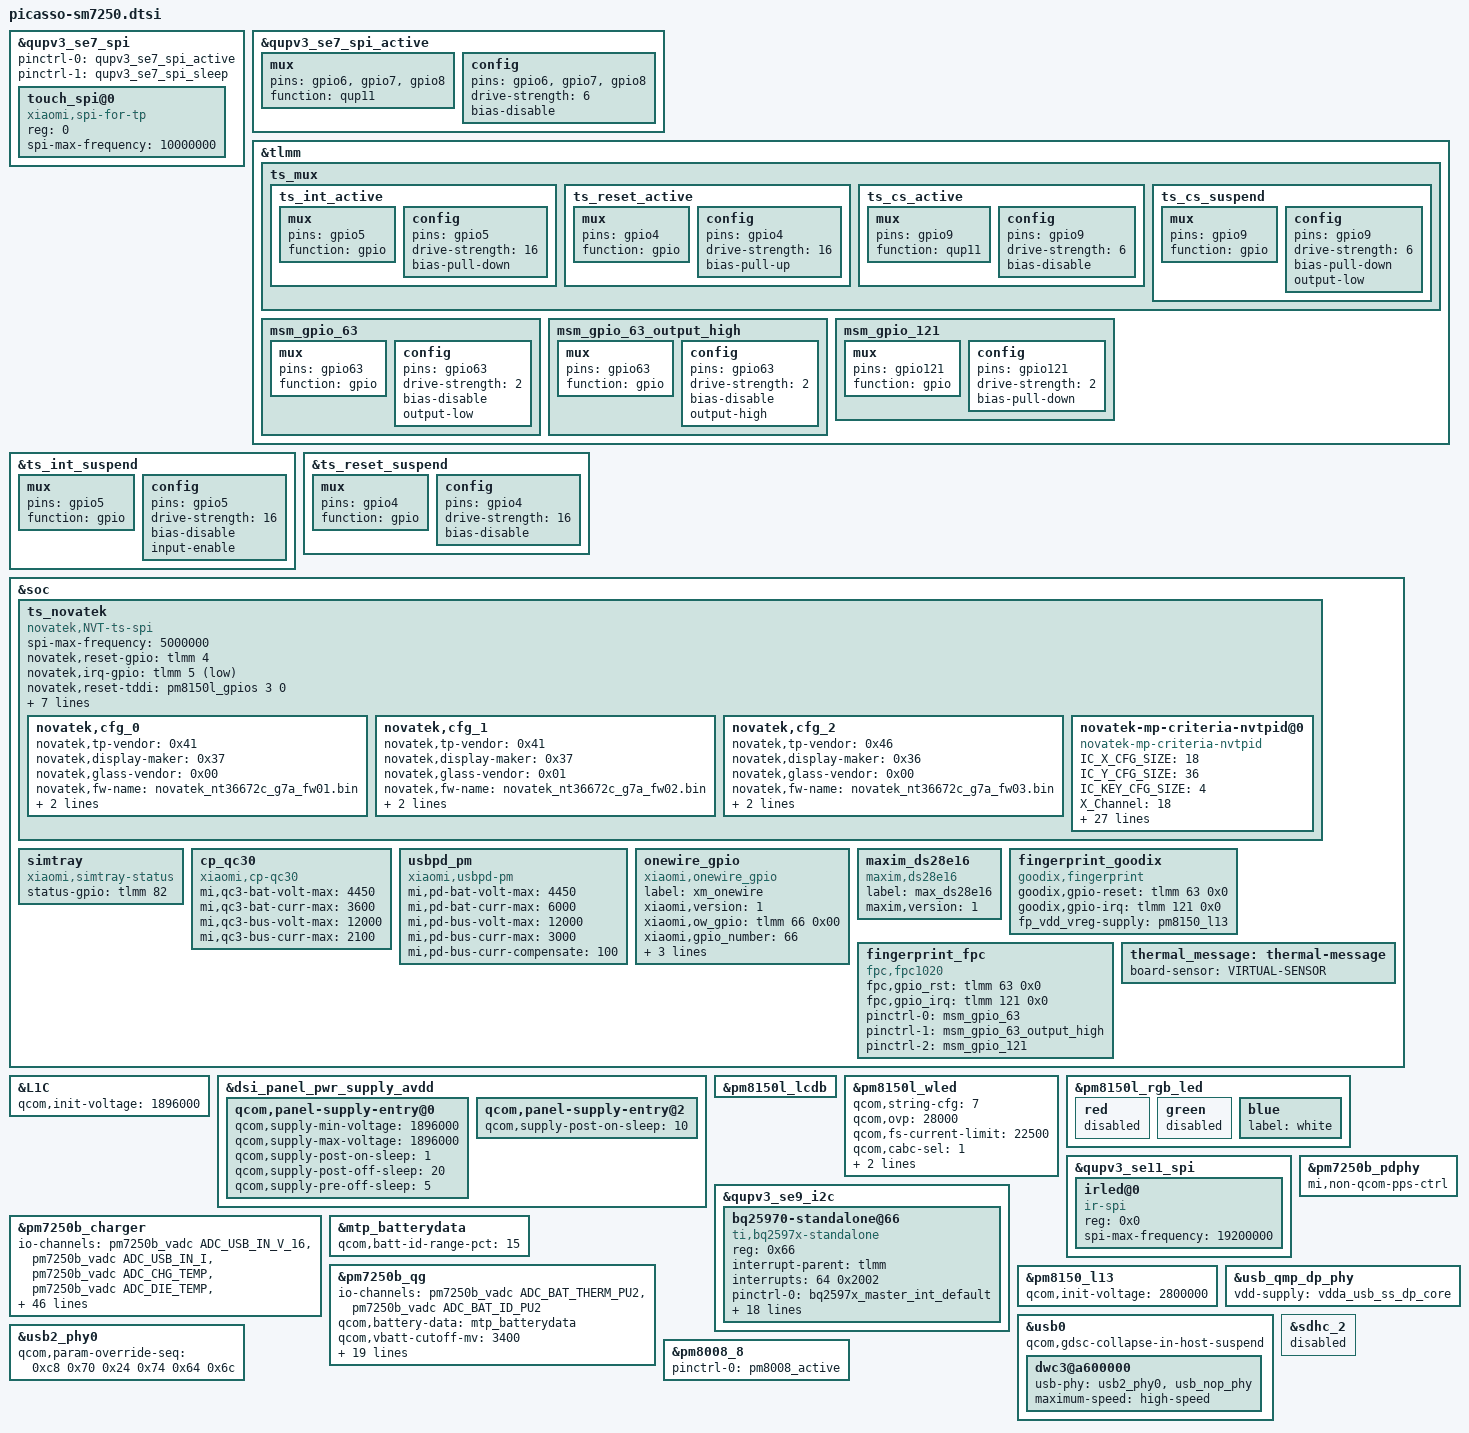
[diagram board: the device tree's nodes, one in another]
/* Copyright (c) 2018, The Linux Foundation. All rights reserved.
 * Copyright (C) 2021 XiaoMi, Inc.
 * Copyright (C) 2021 XiaoMi, Inc.
 *
 * This program is free software; you can redistribute it and/or modify
 * it under the terms of the GNU General Public License version 2 and
 * only version 2 as published by the Free Software Foundation.
 *
 * This program is distributed in the hope that it will be useful,
 * but WITHOUT ANY WARRANTY; without even the implied warranty of
 * MERCHANTABILITY or FITNESS FOR A PARTICULAR PURPOSE.  See the
 * GNU General Public License for more details.
 */

#include "xiaomi-sm7250-common.dtsi"
#include "picasso-sm7250-pinctrl.dtsi"

&qupv3_se7_spi {
	status = "ok";
	touch_spi@0 {
		compatible = "xiaomi,spi-for-tp";
		reg = <0>;
		status = "ok";
		spi-max-frequency = <10000000>;  //10M
	};
};

/*Touch SPI state init*/
&qupv3_se7_spi_active {
	mux {
		pins = "gpio6", "gpio7", "gpio8";
		function = "qup11";
	};

	config {
		pins = "gpio6", "gpio7", "gpio8";
		drive-strength = <6>;
		bias-disable;
	};
};

&qupv3_se7_spi {
	pinctrl-0 = <&qupv3_se7_spi_active>;
	pinctrl-1 = <&qupv3_se7_spi_sleep>;
};

/*IC int pin, rst pin init*/
&tlmm {
	ts_mux {
		ts_int_active: ts_int_active {
			mux {
				pins = "gpio5";
				function = "gpio";
			};

			config {
				pins = "gpio5";
				drive-strength = <16>;
				bias-pull-down;
			};
		};

		ts_reset_active: ts_reset_active {
			mux {
				pins = "gpio4";
				function = "gpio";
			};

			config {
				pins = "gpio4";
				drive-strength = <16>;
				bias-pull-up;
			};
		};
		ts_cs_active: ts_cs_active {
			mux {
				pins = "gpio9";
				function = "qup11";
			};

			config {
				pins = "gpio9";
				drive-strength = <6>;
				bias-disable;
			};
		};

		ts_cs_suspend: ts_cs_suspend {
			mux {
				pins = "gpio9";
				function = "gpio";
			};

			config {
				pins = "gpio9";
				drive-strength = <6>;
				bias-pull-down;
				output-low;
			};
		};
	};
};

&ts_int_suspend {
	mux {
		pins = "gpio5";
		function = "gpio";
	};

	config {
		pins = "gpio5";
		drive-strength = <16>;
		bias-disable;
		input-enable;
	};
};

&ts_reset_suspend {
	mux {
		pins = "gpio4";
		function = "gpio";
	};

	config {
		pins = "gpio4";
		drive-strength = <16>;
		bias-disable;
	};
};


/* Novatek device tree node */
&soc {
	ts_novatek {
			compatible = "novatek,NVT-ts-spi";
			status = "ok";

			spi-max-frequency = <5000000>;	//4800000,9600000,15000000,19200000 5M
			novatek,reset-gpio = <&tlmm 4 0x00>;
			novatek,irq-gpio = <&tlmm 5 0x2001>;
			novatek,reset-tddi = <&pm8150l_gpios 3 0>;
			pinctrl-names = "pmx_ts_active", "pmx_ts_suspend";
			pinctrl-0 = <&ts_int_active &ts_reset_active &ts_cs_active>;
			pinctrl-1 = <&ts_int_suspend &ts_reset_suspend &ts_cs_suspend>;
			/* 672 */
			//novatek,swrst-n8-addr = <0x01F01A>;

			/* 672A */
			novatek,swrst-n8-addr = <0x03F0FE>;
			novatek,spi-rd-fast-addr = <0x03F310>;

			novatek,config-array-size = <3>;
			novatek,cfg_0 {
				novatek,tp-vendor = <0x41>;
				novatek,display-maker = <0x37>;
				novatek,glass-vendor = <0x00>;
				novatek,fw-name = "novatek_nt36672c_g7a_fw01.bin";
				novatek,mp-name = "novatek_nt36672c_g7a_mp01.bin";
				novatek,clicknum-file-name = "nvt+ebbg";
			};
			novatek,cfg_1 {
				novatek,tp-vendor = <0x41>;
				novatek,display-maker = <0x37>;
				novatek,glass-vendor = <0x01>;
				novatek,fw-name = "novatek_nt36672c_g7a_fw02.bin";
				novatek,mp-name = "novatek_nt36672c_g7a_mp02.bin";
				novatek,clicknum-file-name = "nvt+ebbg";
			};
			novatek,cfg_2 {
				novatek,tp-vendor = <0x46>;
				novatek,display-maker = <0x36>;
				novatek,glass-vendor = <0x00>;
				novatek,fw-name = "novatek_nt36672c_g7a_fw03.bin";
				novatek,mp-name = "novatek_nt36672c_g7a_mp03.bin";
				novatek,clicknum-file-name = "nvt+ebbg";
			};

			/* MP */
			//novatek,mp-support-dt;


			novatek-mp-criteria-nvtpid@0 {
				#address-cells = <1>;
				#size-cells = <0>;
				compatible = "novatek-mp-criteria-nvtpid";

				/* MP Config */
				IC_X_CFG_SIZE = <18>;
				IC_Y_CFG_SIZE = <36>;
				IC_KEY_CFG_SIZE = <4>;
				X_Channel = <18>;
				Y_Channel = <36>;
				AIN_X = <0 1 2 3 4 5 6 7 8 9 10 11 12 13 14 15 16 17>;
				AIN_Y = <0 1 2 3 4 5 6 7 8 9 10 11 12 13 14 15 16 17
							18 19 20 21 22 23 24 25 26 27 28 29 30 31 32 33 34 35>;
				AIN_KEY = <0 1 2 0xFF>;

				/* MP Criteria */
				PS_Config_Lmt_Short_Rawdata_P = <
					14008 14008 14008 14008 14008 14008 14008 14008 14008 14008 14008 14008 14008 14008 14008 14008 14008 14008
					14008 14008 14008 14008 14008 14008 14008 14008 14008 14008 14008 14008 14008 14008 14008 14008 14008 14008
					14008 14008 14008 14008 14008 14008 14008 14008 14008 14008 14008 14008 14008 14008 14008 14008 14008 14008
					14008 14008 14008 14008 14008 14008 14008 14008 14008 14008 14008 14008 14008 14008 14008 14008 14008 14008
					14008 14008 14008 14008 14008 14008 14008 14008 14008 14008 14008 14008 14008 14008 14008 14008 14008 14008
					14008 14008 14008 14008 14008 14008 14008 14008 14008 14008 14008 14008 14008 14008 14008 14008 14008 14008
					14008 14008 14008 14008 14008 14008 14008 14008 14008 14008 14008 14008 14008 14008 14008 14008 14008 14008
					14008 14008 14008 14008 14008 14008 14008 14008 14008 14008 14008 14008 14008 14008 14008 14008 14008 14008
					14008 14008 14008 14008 14008 14008 14008 14008 14008 14008 14008 14008 14008 14008 14008 14008 14008 14008
					14008 14008 14008 14008 14008 14008 14008 14008 14008 14008 14008 14008 14008 14008 14008 14008 14008 14008
					14008 14008 14008 14008 14008 14008 14008 14008 14008 14008 14008 14008 14008 14008 14008 14008 14008 14008
					14008 14008 14008 14008 14008 14008 14008 14008 14008 14008 14008 14008 14008 14008 14008 14008 14008 14008
					14008 14008 14008 14008 14008 14008 14008 14008 14008 14008 14008 14008 14008 14008 14008 14008 14008 14008
					14008 14008 14008 14008 14008 14008 14008 14008 14008 14008 14008 14008 14008 14008 14008 14008 14008 14008
					14008 14008 14008 14008 14008 14008 14008 14008 14008 14008 14008 14008 14008 14008 14008 14008 14008 14008
					14008 14008 14008 14008 14008 14008 14008 14008 14008 14008 14008 14008 14008 14008 14008 14008 14008 14008
					14008 14008 14008 14008 14008 14008 14008 14008 14008 14008 14008 14008 14008 14008 14008 14008 14008 14008
					14008 14008 14008 14008 14008 14008 14008 14008 14008 14008 14008 14008 14008 14008 14008 14008 14008 14008
					14008 14008 14008 14008 14008 14008 14008 14008 14008 14008 14008 14008 14008 14008 14008 14008 14008 14008
					14008 14008 14008 14008 14008 14008 14008 14008 14008 14008 14008 14008 14008 14008 14008 14008 14008 14008
					14008 14008 14008 14008 14008 14008 14008 14008 14008 14008 14008 14008 14008 14008 14008 14008 14008 14008
					14008 14008 14008 14008 14008 14008 14008 14008 14008 14008 14008 14008 14008 14008 14008 14008 14008 14008
					14008 14008 14008 14008 14008 14008 14008 14008 14008 14008 14008 14008 14008 14008 14008 14008 14008 14008
					14008 14008 14008 14008 14008 14008 14008 14008 14008 14008 14008 14008 14008 14008 14008 14008 14008 14008
					14008 14008 14008 14008 14008 14008 14008 14008 14008 14008 14008 14008 14008 14008 14008 14008 14008 14008
					14008 14008 14008 14008 14008 14008 14008 14008 14008 14008 14008 14008 14008 14008 14008 14008 14008 14008
					14008 14008 14008 14008 14008 14008 14008 14008 14008 14008 14008 14008 14008 14008 14008 14008 14008 14008
					14008 14008 14008 14008 14008 14008 14008 14008 14008 14008 14008 14008 14008 14008 14008 14008 14008 14008
					14008 14008 14008 14008 14008 14008 14008 14008 14008 14008 14008 14008 14008 14008 14008 14008 14008 14008
					14008 14008 14008 14008 14008 14008 14008 14008 14008 14008 14008 14008 14008 14008 14008 14008 14008 14008
					14008 14008 14008 14008 14008 14008 14008 14008 14008 14008 14008 14008 14008 14008 14008 14008 14008 14008
					14008 14008 14008 14008 14008 14008 14008 14008 14008 14008 14008 14008 14008 14008 14008 14008 14008 14008
					14008 14008 14008 14008 14008 14008 14008 14008 14008 14008 14008 14008 14008 14008 14008 14008 14008 14008
					14008 14008 14008 14008 14008 14008 14008 14008 14008 14008 14008 14008 14008 14008 14008 14008 14008 14008
					14008 14008 14008 14008 14008 14008 14008 14008 14008 14008 14008 14008 14008 14008 14008 14008 14008 14008
					14008 14008 14008 14008 14008 14008 14008 14008 14008 14008 14008 14008 14008 14008 14008 14008 14008 14008
					14008 14008 14008>;

				PS_Config_Lmt_Short_Rawdata_N = <
					10000 10000 10000 10000 10000 10000 10000 10000 10000 10000 10000 10000 10000 10000 10000 10000 10000 10000
					10000 10000 10000 10000 10000 10000 10000 10000 10000 10000 10000 10000 10000 10000 10000 10000 10000 10000
					10000 10000 10000 10000 10000 10000 10000 10000 10000 10000 10000 10000 10000 10000 10000 10000 10000 10000
					10000 10000 10000 10000 10000 10000 10000 10000 10000 10000 10000 10000 10000 10000 10000 10000 10000 10000
					10000 10000 10000 10000 10000 10000 10000 10000 10000 10000 10000 10000 10000 10000 10000 10000 10000 10000
					10000 10000 10000 10000 10000 10000 10000 10000 10000 10000 10000 10000 10000 10000 10000 10000 10000 10000
					10000 10000 10000 10000 10000 10000 10000 10000 10000 10000 10000 10000 10000 10000 10000 10000 10000 10000
					10000 10000 10000 10000 10000 10000 10000 10000 10000 10000 10000 10000 10000 10000 10000 10000 10000 10000
					10000 10000 10000 10000 10000 10000 10000 10000 10000 10000 10000 10000 10000 10000 10000 10000 10000 10000
					10000 10000 10000 10000 10000 10000 10000 10000 10000 10000 10000 10000 10000 10000 10000 10000 10000 10000
					10000 10000 10000 10000 10000 10000 10000 10000 10000 10000 10000 10000 10000 10000 10000 10000 10000 10000
					10000 10000 10000 10000 10000 10000 10000 10000 10000 10000 10000 10000 10000 10000 10000 10000 10000 10000
					10000 10000 10000 10000 10000 10000 10000 10000 10000 10000 10000 10000 10000 10000 10000 10000 10000 10000
					10000 10000 10000 10000 10000 10000 10000 10000 10000 10000 10000 10000 10000 10000 10000 10000 10000 10000
					10000 10000 10000 10000 10000 10000 10000 10000 10000 10000 10000 10000 10000 10000 10000 10000 10000 10000
					10000 10000 10000 10000 10000 10000 10000 10000 10000 10000 10000 10000 10000 10000 10000 10000 10000 10000
					10000 10000 10000 10000 10000 10000 10000 10000 10000 10000 10000 10000 10000 10000 10000 10000 10000 10000
					10000 10000 10000 10000 10000 10000 10000 10000 10000 10000 10000 10000 10000 10000 10000 10000 10000 10000
					10000 10000 10000 10000 10000 10000 10000 10000 10000 10000 10000 10000 10000 10000 10000 10000 10000 10000
					10000 10000 10000 10000 10000 10000 10000 10000 10000 10000 10000 10000 10000 10000 10000 10000 10000 10000
					10000 10000 10000 10000 10000 10000 10000 10000 10000 10000 10000 10000 10000 10000 10000 10000 10000 10000
					10000 10000 10000 10000 10000 10000 10000 10000 10000 10000 10000 10000 10000 10000 10000 10000 10000 10000
					10000 10000 10000 10000 10000 10000 10000 10000 10000 10000 10000 10000 10000 10000 10000 10000 10000 10000
					10000 10000 10000 10000 10000 10000 10000 10000 10000 10000 10000 10000 10000 10000 10000 10000 10000 10000
					10000 10000 10000 10000 10000 10000 10000 10000 10000 10000 10000 10000 10000 10000 10000 10000 10000 10000
					10000 10000 10000 10000 10000 10000 10000 10000 10000 10000 10000 10000 10000 10000 10000 10000 10000 10000
					10000 10000 10000 10000 10000 10000 10000 10000 10000 10000 10000 10000 10000 10000 10000 10000 10000 10000
					10000 10000 10000 10000 10000 10000 10000 10000 10000 10000 10000 10000 10000 10000 10000 10000 10000 10000
					10000 10000 10000 10000 10000 10000 10000 10000 10000 10000 10000 10000 10000 10000 10000 10000 10000 10000
					10000 10000 10000 10000 10000 10000 10000 10000 10000 10000 10000 10000 10000 10000 10000 10000 10000 10000
					10000 10000 10000 10000 10000 10000 10000 10000 10000 10000 10000 10000 10000 10000 10000 10000 10000 10000
					10000 10000 10000 10000 10000 10000 10000 10000 10000 10000 10000 10000 10000 10000 10000 10000 10000 10000
					10000 10000 10000 10000 10000 10000 10000 10000 10000 10000 10000 10000 10000 10000 10000 10000 10000 10000
					10000 10000 10000 10000 10000 10000 10000 10000 10000 10000 10000 10000 10000 10000 10000 10000 10000 10000
					10000 10000 10000 10000 10000 10000 10000 10000 10000 10000 10000 10000 10000 10000 10000 10000 10000 10000
					10000 10000 10000 10000 10000 10000 10000 10000 10000 10000 10000 10000 10000 10000 10000 10000 10000 10000
					10000 10000 10000>;

				PS_Config_Lmt_Open_Rawdata_P = <
					4096 4096 4096 4096 4096 4096 4096 4096 4096 4096 4096 4096 4096 4096 4096 4096 4096 4096
					4096 4096 4096 4096 4096 4096 4096 4096 4096 4096 4096 4096 4096 4096 4096 4096 4096 4096
					4096 4096 4096 4096 4096 4096 4096 4096 4096 4096 4096 4096 4096 4096 4096 4096 4096 4096
					4096 4096 4096 4096 4096 4096 4096 4096 4096 4096 4096 4096 4096 4096 4096 4096 4096 4096
					4096 4096 4096 4096 4096 4096 4096 4096 4096 4096 4096 4096 4096 4096 4096 4096 4096 4096
					4096 4096 4096 4096 4096 4096 4096 4096 4096 4096 4096 4096 4096 4096 4096 4096 4096 4096
					4096 4096 4096 4096 4096 4096 4096 4096 4096 4096 4096 4096 4096 4096 4096 4096 4096 4096
					4096 4096 4096 4096 4096 4096 4096 4096 4096 4096 4096 4096 4096 4096 4096 4096 4096 4096
					4096 4096 4096 4096 4096 4096 4096 4096 4096 4096 4096 4096 4096 4096 4096 4096 4096 4096
					4096 4096 4096 4096 4096 4096 4096 4096 4096 4096 4096 4096 4096 4096 4096 4096 4096 4096
					4096 4096 4096 4096 4096 4096 4096 4096 4096 4096 4096 4096 4096 4096 4096 4096 4096 4096
					4096 4096 4096 4096 4096 4096 4096 4096 4096 4096 4096 4096 4096 4096 4096 4096 4096 4096
					4096 4096 4096 4096 4096 4096 4096 4096 4096 4096 4096 4096 4096 4096 4096 4096 4096 4096
					4096 4096 4096 4096 4096 4096 4096 4096 4096 4096 4096 4096 4096 4096 4096 4096 4096 4096
					4096 4096 4096 4096 4096 4096 4096 4096 4096 4096 4096 4096 4096 4096 4096 4096 4096 4096
					4096 4096 4096 4096 4096 4096 4096 4096 4096 4096 4096 4096 4096 4096 4096 4096 4096 4096
					4096 4096 4096 4096 4096 4096 4096 4096 4096 4096 4096 4096 4096 4096 4096 4096 4096 4096
					4096 4096 4096 4096 4096 4096 4096 4096 4096 4096 4096 4096 4096 4096 4096 4096 4096 4096
					4096 4096 4096 4096 4096 4096 4096 4096 4096 4096 4096 4096 4096 4096 4096 4096 4096 4096
					4096 4096 4096 4096 4096 4096 4096 4096 4096 4096 4096 4096 4096 4096 4096 4096 4096 4096
					4096 4096 4096 4096 4096 4096 4096 4096 4096 4096 4096 4096 4096 4096 4096 4096 4096 4096
					4096 4096 4096 4096 4096 4096 4096 4096 4096 4096 4096 4096 4096 4096 4096 4096 4096 4096
					4096 4096 4096 4096 4096 4096 4096 4096 4096 4096 4096 4096 4096 4096 4096 4096 4096 4096
					4096 4096 4096 4096 4096 4096 4096 4096 4096 4096 4096 4096 4096 4096 4096 4096 4096 4096
					4096 4096 4096 4096 4096 4096 4096 4096 4096 4096 4096 4096 4096 4096 4096 4096 4096 4096
					4096 4096 4096 4096 4096 4096 4096 4096 4096 4096 4096 4096 4096 4096 4096 4096 4096 4096
					4096 4096 4096 4096 4096 4096 4096 4096 4096 4096 4096 4096 4096 4096 4096 4096 4096 4096
					4096 4096 4096 4096 4096 4096 4096 4096 4096 4096 4096 4096 4096 4096 4096 4096 4096 4096
					4096 4096 4096 4096 4096 4096 4096 4096 4096 4096 4096 4096 4096 4096 4096 4096 4096 4096
					4096 4096 4096 4096 4096 4096 4096 4096 4096 4096 4096 4096 4096 4096 4096 4096 4096 4096
					4096 4096 4096 4096 4096 4096 4096 4096 4096 4096 4096 4096 4096 4096 4096 4096 4096 4096
					4096 4096 4096 4096 4096 4096 4096 4096 4096 4096 4096 4096 4096 4096 4096 4096 4096 4096
					4096 4096 4096 4096 4096 4096 4096 4096 4096 4096 4096 4096 4096 4096 4096 4096 4096 4096
					4096 4096 4096 4096 4096 4096 4096 4096 4096 4096 4096 4096 4096 4096 4096 4096 4096 4096
					4096 4096 4096 4096 4096 4096 4096 4096 4096 4096 4096 4096 4096 4096 4096 4096 4096 4096
					4096 4096 4096 4096 4096 4096 4096 4096 4096 4096 4096 4096 4096 4096 4096 4096 4096 4096
					4096 4096 4096>;

				PS_Config_Lmt_Open_Rawdata_N = <
					50 50 50 50 50 50 50 50 50 50 50 50 50 50 50 50 50 50
					50 50 50 50 50 50 50 50 50 50 50 50 50 50 50 50 50 50
					50 50 50 50 50 50 50 50 50 50 50 50 50 50 50 50 50 50
					50 50 50 50 50 50 50 50 50 50 50 50 50 50 50 50 50 50
					50 50 50 50 50 50 50 50 50 50 50 50 50 50 50 50 50 50
					50 50 50 50 50 50 50 50 50 50 50 50 50 50 50 50 50 50
					50 50 50 50 50 50 50 50 50 50 50 50 50 50 50 50 50 50
					50 50 50 50 50 50 50 50 50 50 50 50 50 50 50 50 50 50
					50 50 50 50 50 50 50 50 50 50 50 50 50 50 50 50 50 50
					50 50 50 50 50 50 50 50 50 50 50 50 50 50 50 50 50 50
					50 50 50 50 50 50 50 50 50 50 50 50 50 50 50 50 50 50
					50 50 50 50 50 50 50 50 50 50 50 50 50 50 50 50 50 50
					50 50 50 50 50 50 50 50 50 50 50 50 50 50 50 50 50 50
					50 50 50 50 50 50 50 50 50 50 50 50 50 50 50 50 50 50
					50 50 50 50 50 50 50 50 50 50 50 50 50 50 50 50 50 50
					50 50 50 50 50 50 50 50 50 50 50 50 50 50 50 50 50 50
					50 50 50 50 50 50 50 50 50 50 50 50 50 50 50 50 50 50
					50 50 50 50 50 50 50 50 50 50 50 50 50 50 50 50 50 50
					50 50 50 50 50 50 50 50 50 50 50 50 50 50 50 50 50 50
					50 50 50 50 50 50 50 50 50 50 50 50 50 50 50 50 50 50
					50 50 50 50 50 50 50 50 50 50 50 50 50 50 50 50 50 50
					50 50 50 50 50 50 50 50 50 50 50 50 50 50 50 50 50 50
					50 50 50 50 50 50 50 50 50 50 50 50 50 50 50 50 50 50
					50 50 50 50 50 50 50 50 50 50 50 50 50 50 50 50 50 50
					50 50 50 50 50 50 50 50 50 50 50 50 50 50 50 50 50 50
					50 50 50 50 50 50 50 50 50 50 50 50 50 50 50 50 50 50
					50 50 50 50 50 50 50 50 50 50 50 50 50 50 50 50 50 50
					50 50 50 50 50 50 50 50 50 50 50 50 50 50 50 50 50 50
					50 50 50 50 50 50 50 50 50 50 50 50 50 50 50 50 50 50
					50 50 50 50 50 50 50 50 50 50 50 50 50 50 50 50 50 50
					50 50 50 50 50 50 50 50 50 50 50 50 50 50 50 50 50 50
					50 50 50 50 50 50 50 50 50 50 50 50 50 50 50 50 50 50
					50 50 50 50 50 50 50 50 50 50 50 50 50 50 50 50 50 50
					50 50 50 50 50 50 50 50 50 50 50 50 50 50 50 50 50 50
					50 50 50 50 50 50 50 50 50 50 50 50 50 50 50 50 50 50
					50 50 50 50 50 50 50 50 50 50 50 50 50 50 50 50 50 50
					50 50 50>;

				PS_Config_Lmt_FW_Rawdata_P = <
					1920 1920 1920 1920 1920 1920 1920 1920 1920 1920 1920 1920 1920 1920 1920 1920 1920 1920
					1920 1920 1920 1920 1920 1920 1920 1920 1920 1920 1920 1920 1920 1920 1920 1920 1920 1920
					1920 1920 1920 1920 1920 1920 1920 1920 1920 1920 1920 1920 1920 1920 1920 1920 1920 1920
					1920 1920 1920 1920 1920 1920 1920 1920 1920 1920 1920 1920 1920 1920 1920 1920 1920 1920
					1920 1920 1920 1920 1920 1920 1920 1920 1920 1920 1920 1920 1920 1920 1920 1920 1920 1920
					1920 1920 1920 1920 1920 1920 1920 1920 1920 1920 1920 1920 1920 1920 1920 1920 1920 1920
					1920 1920 1920 1920 1920 1920 1920 1920 1920 1920 1920 1920 1920 1920 1920 1920 1920 1920
					1920 1920 1920 1920 1920 1920 1920 1920 1920 1920 1920 1920 1920 1920 1920 1920 1920 1920
					1920 1920 1920 1920 1920 1920 1920 1920 1920 1920 1920 1920 1920 1920 1920 1920 1920 1920
					1920 1920 1920 1920 1920 1920 1920 1920 1920 1920 1920 1920 1920 1920 1920 1920 1920 1920
					1920 1920 1920 1920 1920 1920 1920 1920 1920 1920 1920 1920 1920 1920 1920 1920 1920 1920
					1920 1920 1920 1920 1920 1920 1920 1920 1920 1920 1920 1920 1920 1920 1920 1920 1920 1920
					1920 1920 1920 1920 1920 1920 1920 1920 1920 1920 1920 1920 1920 1920 1920 1920 1920 1920
					1920 1920 1920 1920 1920 1920 1920 1920 1920 1920 1920 1920 1920 1920 1920 1920 1920 1920
					1920 1920 1920 1920 1920 1920 1920 1920 1920 1920 1920 1920 1920 1920 1920 1920 1920 1920
					1920 1920 1920 1920 1920 1920 1920 1920 1920 1920 1920 1920 1920 1920 1920 1920 1920 1920
					1920 1920 1920 1920 1920 1920 1920 1920 1920 1920 1920 1920 1920 1920 1920 1920 1920 1920
					1920 1920 1920 1920 1920 1920 1920 1920 1920 1920 1920 1920 1920 1920 1920 1920 1920 1920
					1920 1920 1920 1920 1920 1920 1920 1920 1920 1920 1920 1920 1920 1920 1920 1920 1920 1920
					1920 1920 1920 1920 1920 1920 1920 1920 1920 1920 1920 1920 1920 1920 1920 1920 1920 1920
					1920 1920 1920 1920 1920 1920 1920 1920 1920 1920 1920 1920 1920 1920 1920 1920 1920 1920
					1920 1920 1920 1920 1920 1920 1920 1920 1920 1920 1920 1920 1920 1920 1920 1920 1920 1920
					1920 1920 1920 1920 1920 1920 1920 1920 1920 1920 1920 1920 1920 1920 1920 1920 1920 1920
					1920 1920 1920 1920 1920 1920 1920 1920 1920 1920 1920 1920 1920 1920 1920 1920 1920 1920
					1920 1920 1920 1920 1920 1920 1920 1920 1920 1920 1920 1920 1920 1920 1920 1920 1920 1920
					1920 1920 1920 1920 1920 1920 1920 1920 1920 1920 1920 1920 1920 1920 1920 1920 1920 1920
					1920 1920 1920 1920 1920 1920 1920 1920 1920 1920 1920 1920 1920 1920 1920 1920 1920 1920
					1920 1920 1920 1920 1920 1920 1920 1920 1920 1920 1920 1920 1920 1920 1920 1920 1920 1920
					1920 1920 1920 1920 1920 1920 1920 1920 1920 1920 1920 1920 1920 1920 1920 1920 1920 1920
					1920 1920 1920 1920 1920 1920 1920 1920 1920 1920 1920 1920 1920 1920 1920 1920 1920 1920
					1920 1920 1920 1920 1920 1920 1920 1920 1920 1920 1920 1920 1920 1920 1920 1920 1920 1920
					1920 1920 1920 1920 1920 1920 1920 1920 1920 1920 1920 1920 1920 1920 1920 1920 1920 1920
					1920 1920 1920 1920 1920 1920 1920 1920 1920 1920 1920 1920 1920 1920 1920 1920 1920 1920
					1920 1920 1920 1920 1920 1920 1920 1920 1920 1920 1920 1920 1920 1920 1920 1920 1920 1920
					1920 1920 1920 1920 1920 1920 1920 1920 1920 1920 1920 1920 1920 1920 1920 1920 1920 1920
					1920 1920 1920 1920 1920 1920 1920 1920 1920 1920 1920 1920 1920 1920 1920 1920 1920 1920
					1920 1920 1920>;

				PS_Config_Lmt_FW_Rawdata_N = <
					240 240 240 240 240 240 240 240 240 240 240 240 240 240 240 240 240 240
					240 240 240 240 240 240 240 240 240 240 240 240 240 240 240 240 240 240
					240 240 240 240 240 240 240 240 240 240 240 240 240 240 240 240 240 240
					240 240 240 240 240 240 240 240 240 240 240 240 240 240 240 240 240 240
					240 240 240 240 240 240 240 240 240 240 240 240 240 240 240 240 240 240
					240 240 240 240 240 240 240 240 240 240 240 240 240 240 240 240 240 240
					240 240 240 240 240 240 240 240 240 240 240 240 240 240 240 240 240 240
					240 240 240 240 240 240 240 240 240 240 240 240 240 240 240 240 240 240
					240 240 240 240 240 240 240 240 240 240 240 240 240 240 240 240 240 240
					240 240 240 240 240 240 240 240 240 240 240 240 240 240 240 240 240 240
					240 240 240 240 240 240 240 240 240 240 240 240 240 240 240 240 240 240
					240 240 240 240 240 240 240 240 240 240 240 240 240 240 240 240 240 240
					240 240 240 240 240 240 240 240 240 240 240 240 240 240 240 240 240 240
					240 240 240 240 240 240 240 240 240 240 240 240 240 240 240 240 240 240
					240 240 240 240 240 240 240 240 240 240 240 240 240 240 240 240 240 240
					240 240 240 240 240 240 240 240 240 240 240 240 240 240 240 240 240 240
					240 240 240 240 240 240 240 240 240 240 240 240 240 240 240 240 240 240
					240 240 240 240 240 240 240 240 240 240 240 240 240 240 240 240 240 240
					240 240 240 240 240 240 240 240 240 240 240 240 240 240 240 240 240 240
					240 240 240 240 240 240 240 240 240 240 240 240 240 240 240 240 240 240
					240 240 240 240 240 240 240 240 240 240 240 240 240 240 240 240 240 240
					240 240 240 240 240 240 240 240 240 240 240 240 240 240 240 240 240 240
					240 240 240 240 240 240 240 240 240 240 240 240 240 240 240 240 240 240
					240 240 240 240 240 240 240 240 240 240 240 240 240 240 240 240 240 240
					240 240 240 240 240 240 240 240 240 240 240 240 240 240 240 240 240 240
					240 240 240 240 240 240 240 240 240 240 240 240 240 240 240 240 240 240
					240 240 240 240 240 240 240 240 240 240 240 240 240 240 240 240 240 240
					240 240 240 240 240 240 240 240 240 240 240 240 240 240 240 240 240 240
					240 240 240 240 240 240 240 240 240 240 240 240 240 240 240 240 240 240
					240 240 240 240 240 240 240 240 240 240 240 240 240 240 240 240 240 240
					240 240 240 240 240 240 240 240 240 240 240 240 240 240 240 240 240 240
					240 240 240 240 240 240 240 240 240 240 240 240 240 240 240 240 240 240
					240 240 240 240 240 240 240 240 240 240 240 240 240 240 240 240 240 240
					240 240 240 240 240 240 240 240 240 240 240 240 240 240 240 240 240 240
					240 240 240 240 240 240 240 240 240 240 240 240 240 240 240 240 240 240
					240 240 240 240 240 240 240 240 240 240 240 240 240 240 240 240 240 240
					240 240 240>;

				PS_Config_Lmt_FW_CC_P = <
					314 314 314 314 314 314 314 314 314 314 314 314 314 314 314 314 314 314
					314 314 314 314 314 314 314 314 314 314 314 314 314 314 314 314 314 314
					314 314 314 314 314 314 314 314 314 314 314 314 314 314 314 314 314 314
					314 314 314 314 314 314 314 314 314 314 314 314 314 314 314 314 314 314
					314 314 314 314 314 314 314 314 314 314 314 314 314 314 314 314 314 314
					314 314 314 314 314 314 314 314 314 314 314 314 314 314 314 314 314 314
					314 314 314 314 314 314 314 314 314 314 314 314 314 314 314 314 314 314
					314 314 314 314 314 314 314 314 314 314 314 314 314 314 314 314 314 314
					314 314 314 314 314 314 314 314 314 314 314 314 314 314 314 314 314 314
					314 314 314 314 314 314 314 314 314 314 314 314 314 314 314 314 314 314
					314 314 314 314 314 314 314 314 314 314 314 314 314 314 314 314 314 314
					314 314 314 314 314 314 314 314 314 314 314 314 314 314 314 314 314 314
					314 314 314 314 314 314 314 314 314 314 314 314 314 314 314 314 314 314
					314 314 314 314 314 314 314 314 314 314 314 314 314 314 314 314 314 314
					314 314 314 314 314 314 314 314 314 314 314 314 314 314 314 314 314 314
					314 314 314 314 314 314 314 314 314 314 314 314 314 314 314 314 314 314
					314 314 314 314 314 314 314 314 314 314 314 314 314 314 314 314 314 314
					314 314 314 314 314 314 314 314 314 314 314 314 314 314 314 314 314 314
					314 314 314 314 314 314 314 314 314 314 314 314 314 314 314 314 314 314
					314 314 314 314 314 314 314 314 314 314 314 314 314 314 314 314 314 314
					314 314 314 314 314 314 314 314 314 314 314 314 314 314 314 314 314 314
					314 314 314 314 314 314 314 314 314 314 314 314 314 314 314 314 314 314
					314 314 314 314 314 314 314 314 314 314 314 314 314 314 314 314 314 314
					314 314 314 314 314 314 314 314 314 314 314 314 314 314 314 314 314 314
					314 314 314 314 314 314 314 314 314 314 314 314 314 314 314 314 314 314
					314 314 314 314 314 314 314 314 314 314 314 314 314 314 314 314 314 314
					314 314 314 314 314 314 314 314 314 314 314 314 314 314 314 314 314 314
					314 314 314 314 314 314 314 314 314 314 314 314 314 314 314 314 314 314
					314 314 314 314 314 314 314 314 314 314 314 314 314 314 314 314 314 314
					314 314 314 314 314 314 314 314 314 314 314 314 314 314 314 314 314 314
					314 314 314 314 314 314 314 314 314 314 314 314 314 314 314 314 314 314
					314 314 314 314 314 314 314 314 314 314 314 314 314 314 314 314 314 314
					314 314 314 314 314 314 314 314 314 314 314 314 314 314 314 314 314 314
					314 314 314 314 314 314 314 314 314 314 314 314 314 314 314 314 314 314
					314 314 314 314 314 314 314 314 314 314 314 314 314 314 314 314 314 314
					314 314 314 314 314 314 314 314 314 314 314 314 314 314 314 314 314 314
					314 314 314>;

				PS_Config_Lmt_FW_CC_N = <
					30 30 30 30 30 30 30 30 30 30 30 30 30 30 30 30 30 30
					30 30 30 30 30 30 30 30 30 30 30 30 30 30 30 30 30 30
					30 30 30 30 30 30 30 30 30 30 30 30 30 30 30 30 30 30
					30 30 30 30 30 30 30 30 30 30 30 30 30 30 30 30 30 30
					30 30 30 30 30 30 30 30 30 30 30 30 30 30 30 30 30 30
					30 30 30 30 30 30 30 30 30 30 30 30 30 30 30 30 30 30
					30 30 30 30 30 30 30 30 30 30 30 30 30 30 30 30 30 30
					30 30 30 30 30 30 30 30 30 30 30 30 30 30 30 30 30 30
					30 30 30 30 30 30 30 30 30 30 30 30 30 30 30 30 30 30
					30 30 30 30 30 30 30 30 30 30 30 30 30 30 30 30 30 30
					30 30 30 30 30 30 30 30 30 30 30 30 30 30 30 30 30 30
					30 30 30 30 30 30 30 30 30 30 30 30 30 30 30 30 30 30
					30 30 30 30 30 30 30 30 30 30 30 30 30 30 30 30 30 30
					30 30 30 30 30 30 30 30 30 30 30 30 30 30 30 30 30 30
					30 30 30 30 30 30 30 30 30 30 30 30 30 30 30 30 30 30
					30 30 30 30 30 30 30 30 30 30 30 30 30 30 30 30 30 30
					30 30 30 30 30 30 30 30 30 30 30 30 30 30 30 30 30 30
					30 30 30 30 30 30 30 30 30 30 30 30 30 30 30 30 30 30
					30 30 30 30 30 30 30 30 30 30 30 30 30 30 30 30 30 30
					30 30 30 30 30 30 30 30 30 30 30 30 30 30 30 30 30 30
					30 30 30 30 30 30 30 30 30 30 30 30 30 30 30 30 30 30
					30 30 30 30 30 30 30 30 30 30 30 30 30 30 30 30 30 30
					30 30 30 30 30 30 30 30 30 30 30 30 30 30 30 30 30 30
					30 30 30 30 30 30 30 30 30 30 30 30 30 30 30 30 30 30
					30 30 30 30 30 30 30 30 30 30 30 30 30 30 30 30 30 30
					30 30 30 30 30 30 30 30 30 30 30 30 30 30 30 30 30 30
					30 30 30 30 30 30 30 30 30 30 30 30 30 30 30 30 30 30
					30 30 30 30 30 30 30 30 30 30 30 30 30 30 30 30 30 30
					30 30 30 30 30 30 30 30 30 30 30 30 30 30 30 30 30 30
					30 30 30 30 30 30 30 30 30 30 30 30 30 30 30 30 30 30
					30 30 30 30 30 30 30 30 30 30 30 30 30 30 30 30 30 30
					30 30 30 30 30 30 30 30 30 30 30 30 30 30 30 30 30 30
					30 30 30 30 30 30 30 30 30 30 30 30 30 30 30 30 30 30
					30 30 30 30 30 30 30 30 30 30 30 30 30 30 30 30 30 30
					30 30 30 30 30 30 30 30 30 30 30 30 30 30 30 30 30 30
					30 30 30 30 30 30 30 30 30 30 30 30 30 30 30 30 30 30
					30 30 30>;

				PS_Config_Lmt_FW_Diff_P = <
					75 75 75 75 75 75 75 75 75 75 75 75 75 75 75 75 75 75
					75 75 75 75 75 75 75 75 75 75 75 75 75 75 75 75 75 75
					75 75 75 75 75 75 75 75 75 75 75 75 75 75 75 75 75 75
					75 75 75 75 75 75 75 75 75 75 75 75 75 75 75 75 75 75
					75 75 75 75 75 75 75 75 75 75 75 75 75 75 75 75 75 75
					75 75 75 75 75 75 75 75 75 75 75 75 75 75 75 75 75 75
					75 75 75 75 75 75 75 75 75 75 75 75 75 75 75 75 75 75
					75 75 75 75 75 75 75 75 75 75 75 75 75 75 75 75 75 75
					75 75 75 75 75 75 75 75 75 75 75 75 75 75 75 75 75 75
					75 75 75 75 75 75 75 75 75 75 75 75 75 75 75 75 75 75
					75 75 75 75 75 75 75 75 75 75 75 75 75 75 75 75 75 75
					75 75 75 75 75 75 75 75 75 75 75 75 75 75 75 75 75 75
					75 75 75 75 75 75 75 75 75 75 75 75 75 75 75 75 75 75
					75 75 75 75 75 75 75 75 75 75 75 75 75 75 75 75 75 75
					75 75 75 75 75 75 75 75 75 75 75 75 75 75 75 75 75 75
					75 75 75 75 75 75 75 75 75 75 75 75 75 75 75 75 75 75
					75 75 75 75 75 75 75 75 75 75 75 75 75 75 75 75 75 75
					75 75 75 75 75 75 75 75 75 75 75 75 75 75 75 75 75 75
					75 75 75 75 75 75 75 75 75 75 75 75 75 75 75 75 75 75
					75 75 75 75 75 75 75 75 75 75 75 75 75 75 75 75 75 75
					75 75 75 75 75 75 75 75 75 75 75 75 75 75 75 75 75 75
					75 75 75 75 75 75 75 75 75 75 75 75 75 75 75 75 75 75
					75 75 75 75 75 75 75 75 75 75 75 75 75 75 75 75 75 75
					75 75 75 75 75 75 75 75 75 75 75 75 75 75 75 75 75 75
					75 75 75 75 75 75 75 75 75 75 75 75 75 75 75 75 75 75
					75 75 75 75 75 75 75 75 75 75 75 75 75 75 75 75 75 75
					75 75 75 75 75 75 75 75 75 75 75 75 75 75 75 75 75 75
					75 75 75 75 75 75 75 75 75 75 75 75 75 75 75 75 75 75
					75 75 75 75 75 75 75 75 75 75 75 75 75 75 75 75 75 75
					75 75 75 75 75 75 75 75 75 75 75 75 75 75 75 75 75 75
					75 75 75 75 75 75 75 75 75 75 75 75 75 75 75 75 75 75
					75 75 75 75 75 75 75 75 75 75 75 75 75 75 75 75 75 75
					75 75 75 75 75 75 75 75 75 75 75 75 75 75 75 75 75 75
					75 75 75 75 75 75 75 75 75 75 75 75 75 75 75 75 75 75
					75 75 75 75 75 75 75 75 75 75 75 75 75 75 75 75 75 75
					75 75 75 75 75 75 75 75 75 75 75 75 75 75 75 75 75 75
					75 75 75>;

				PS_Config_Lmt_FW_Diff_N = <
					(-75) (-75) (-75) (-75) (-75) (-75) (-75) (-75) (-75) (-75) (-75) (-75) (-75) (-75) (-75) (-75) (-75) (-75)
					(-75) (-75) (-75) (-75) (-75) (-75) (-75) (-75) (-75) (-75) (-75) (-75) (-75) (-75) (-75) (-75) (-75) (-75)
					(-75) (-75) (-75) (-75) (-75) (-75) (-75) (-75) (-75) (-75) (-75) (-75) (-75) (-75) (-75) (-75) (-75) (-75)
					(-75) (-75) (-75) (-75) (-75) (-75) (-75) (-75) (-75) (-75) (-75) (-75) (-75) (-75) (-75) (-75) (-75) (-75)
					(-75) (-75) (-75) (-75) (-75) (-75) (-75) (-75) (-75) (-75) (-75) (-75) (-75) (-75) (-75) (-75) (-75) (-75)
					(-75) (-75) (-75) (-75) (-75) (-75) (-75) (-75) (-75) (-75) (-75) (-75) (-75) (-75) (-75) (-75) (-75) (-75)
					(-75) (-75) (-75) (-75) (-75) (-75) (-75) (-75) (-75) (-75) (-75) (-75) (-75) (-75) (-75) (-75) (-75) (-75)
					(-75) (-75) (-75) (-75) (-75) (-75) (-75) (-75) (-75) (-75) (-75) (-75) (-75) (-75) (-75) (-75) (-75) (-75)
					(-75) (-75) (-75) (-75) (-75) (-75) (-75) (-75) (-75) (-75) (-75) (-75) (-75) (-75) (-75) (-75) (-75) (-75)
					(-75) (-75) (-75) (-75) (-75) (-75) (-75) (-75) (-75) (-75) (-75) (-75) (-75) (-75) (-75) (-75) (-75) (-75)
					(-75) (-75) (-75) (-75) (-75) (-75) (-75) (-75) (-75) (-75) (-75) (-75) (-75) (-75) (-75) (-75) (-75) (-75)
					(-75) (-75) (-75) (-75) (-75) (-75) (-75) (-75) (-75) (-75) (-75) (-75) (-75) (-75) (-75) (-75) (-75) (-75)
					(-75) (-75) (-75) (-75) (-75) (-75) (-75) (-75) (-75) (-75) (-75) (-75) (-75) (-75) (-75) (-75) (-75) (-75)
					(-75) (-75) (-75) (-75) (-75) (-75) (-75) (-75) (-75) (-75) (-75) (-75) (-75) (-75) (-75) (-75) (-75) (-75)
					(-75) (-75) (-75) (-75) (-75) (-75) (-75) (-75) (-75) (-75) (-75) (-75) (-75) (-75) (-75) (-75) (-75) (-75)
					(-75) (-75) (-75) (-75) (-75) (-75) (-75) (-75) (-75) (-75) (-75) (-75) (-75) (-75) (-75) (-75) (-75) (-75)
					(-75) (-75) (-75) (-75) (-75) (-75) (-75) (-75) (-75) (-75) (-75) (-75) (-75) (-75) (-75) (-75) (-75) (-75)
					(-75) (-75) (-75) (-75) (-75) (-75) (-75) (-75) (-75) (-75) (-75) (-75) (-75) (-75) (-75) (-75) (-75) (-75)
					(-75) (-75) (-75) (-75) (-75) (-75) (-75) (-75) (-75) (-75) (-75) (-75) (-75) (-75) (-75) (-75) (-75) (-75)
					(-75) (-75) (-75) (-75) (-75) (-75) (-75) (-75) (-75) (-75) (-75) (-75) (-75) (-75) (-75) (-75) (-75) (-75)
					(-75) (-75) (-75) (-75) (-75) (-75) (-75) (-75) (-75) (-75) (-75) (-75) (-75) (-75) (-75) (-75) (-75) (-75)
					(-75) (-75) (-75) (-75) (-75) (-75) (-75) (-75) (-75) (-75) (-75) (-75) (-75) (-75) (-75) (-75) (-75) (-75)
					(-75) (-75) (-75) (-75) (-75) (-75) (-75) (-75) (-75) (-75) (-75) (-75) (-75) (-75) (-75) (-75) (-75) (-75)
					(-75) (-75) (-75) (-75) (-75) (-75) (-75) (-75) (-75) (-75) (-75) (-75) (-75) (-75) (-75) (-75) (-75) (-75)
					(-75) (-75) (-75) (-75) (-75) (-75) (-75) (-75) (-75) (-75) (-75) (-75) (-75) (-75) (-75) (-75) (-75) (-75)
					(-75) (-75) (-75) (-75) (-75) (-75) (-75) (-75) (-75) (-75) (-75) (-75) (-75) (-75) (-75) (-75) (-75) (-75)
					(-75) (-75) (-75) (-75) (-75) (-75) (-75) (-75) (-75) (-75) (-75) (-75) (-75) (-75) (-75) (-75) (-75) (-75)
					(-75) (-75) (-75) (-75) (-75) (-75) (-75) (-75) (-75) (-75) (-75) (-75) (-75) (-75) (-75) (-75) (-75) (-75)
					(-75) (-75) (-75) (-75) (-75) (-75) (-75) (-75) (-75) (-75) (-75) (-75) (-75) (-75) (-75) (-75) (-75) (-75)
					(-75) (-75) (-75) (-75) (-75) (-75) (-75) (-75) (-75) (-75) (-75) (-75) (-75) (-75) (-75) (-75) (-75) (-75)
					(-75) (-75) (-75) (-75) (-75) (-75) (-75) (-75) (-75) (-75) (-75) (-75) (-75) (-75) (-75) (-75) (-75) (-75)
					(-75) (-75) (-75) (-75) (-75) (-75) (-75) (-75) (-75) (-75) (-75) (-75) (-75) (-75) (-75) (-75) (-75) (-75)
					(-75) (-75) (-75) (-75) (-75) (-75) (-75) (-75) (-75) (-75) (-75) (-75) (-75) (-75) (-75) (-75) (-75) (-75)
					(-75) (-75) (-75) (-75) (-75) (-75) (-75) (-75) (-75) (-75) (-75) (-75) (-75) (-75) (-75) (-75) (-75) (-75)
					(-75) (-75) (-75) (-75) (-75) (-75) (-75) (-75) (-75) (-75) (-75) (-75) (-75) (-75) (-75) (-75) (-75) (-75)
					(-75) (-75) (-75) (-75) (-75) (-75) (-75) (-75) (-75) (-75) (-75) (-75) (-75) (-75) (-75) (-75) (-75) (-75)
					(-75) (-75) (-75)>;

				PS_Config_Diff_Test_Frame = <50>;
			};
	};

	simtray {
		compatible = "xiaomi,simtray-status";
		status-gpio = <&tlmm 82 0x00>;
	};
};

&L1C {
	qcom,init-voltage = <1896000>;
};

&dsi_panel_pwr_supply_avdd {
	qcom,panel-supply-entry@0 {
		qcom,supply-min-voltage = <1896000>;
		qcom,supply-max-voltage = <1896000>;
		qcom,supply-post-on-sleep = <1>;
		qcom,supply-post-off-sleep = <20>;
		qcom,supply-pre-off-sleep = <5>;
	};

	qcom,panel-supply-entry@2 {
		qcom,supply-post-on-sleep = <10>;
	};
};

&pm8150l_lcdb {
	status = "okay";
};

&pm8150l_wled {
	status = "okay";
	qcom,string-cfg = <7>;
	qcom,ovp = <28000>;
	qcom,fs-current-limit = <22500>;
	qcom,cabc-sel = <1>;
	mi,cabcoff-dbv = <200>;
	mi,cabc-pwm = <2924 4095>;
};

&pm8150l_rgb_led {
	red {
		status = "disabled";
	};

	green {
		status = "disabled";
	};

	blue {
		label = "white";
	};
};

&qupv3_se11_spi {
	status = "ok";
	irled@0 {
		compatible = "ir-spi";
		reg = <0x0>;
		status = "ok";
		spi-max-frequency = <19200000>;
	};
};

&qupv3_se9_i2c {
	#address-cells = <1>;
	#size-cells = <0>;
	status = "ok";
	bq25970-standalone@66 {
		compatible = "ti,bq2597x-standalone";
		reg = <0x66>;
		interrupt-parent = <&tlmm>;
		interrupts = <64 0x2002>;
		pinctrl-names = "default";
		pinctrl-0 = <&bq2597x_master_int_default>;

		/*ti,bq2597x,bat-ovp-disable;*/
		ti,bq2597x,bat-ovp-alarm-disable;
		ti,bq2597x,bat-ocp-disable;
		ti,bq2597x,bat-ocp-alarm-disable;
		ti,bq2597x,bat-ucp-alarm-disable;
		ti,bq2597x,bat-ucp-disable;

		/*ti,bq2597x,bus-ovp-alarm-disable;
		  ti,bq2597x,bus-ocp-disable;
		  ti,bq2597x,bus-ocp-alarm-disable;*/
		ti,bq2597x,bat-therm-disable;
		ti,bq2597x,bus-therm-disable;
		ti,bq2597x,die-therm-disable;

		ti,bq2597x,bat-ovp-threshold = <4480>;
		ti,bq2597x,bat-ovp-alarm-threshold = <4450>;
		//ti,bq2597x,bat-ocp-threshold = <8000>;
		//ti,bq2597x,bat-ocp-alarm-threshold = <7500>;

		ti,bq2597x,bus-ovp-threshold = <12000>;
		ti,bq2597x,bus-ovp-alarm-threshold = <11000>;
		ti,bq2597x,bus-ocp-threshold = <4000>;
		ti,bq2597x,bus-ocp-alarm-threshold = <4000>;

		//ti,bq2597x,bat-ucp-alarm-threshold = <2000>;

		ti,bq2597x,bat-therm-threshold = <0x15>;/*4.1%*/
		ti,bq2597x,bus-therm-threshold = <0x15>;/*4.1%*/
		ti,bq2597x,die-therm-threshold = <145>;

		ti,bq2597x,ac-ovp-threshold = <14>;
		//ti,bq2597x,sense-resistor-mohm = <2>;

	};
};

&pm7250b_charger {
	status = "ok";
	io-channels =
		<&pm7250b_vadc ADC_USB_IN_V_16>,
		<&pm7250b_vadc ADC_USB_IN_I>,
		<&pm7250b_vadc ADC_CHG_TEMP>,
		<&pm7250b_vadc ADC_DIE_TEMP>,
		<&pm7250b_vadc ADC_AMUX_THM3_PU2>,
		<&pm7250b_vadc ADC_SBUx>,
		<&pm7250b_vadc ADC_VPH_PWR>;
	io-channel-names =
		"usb_in_voltage",
		"usb_in_current",
		"chg_temp",
		"die_temp",
		"conn_temp",
		"sbux_res",
		"vph_voltage";
	qcom,battery-data = <&mtp_batterydata>;
	qcom,sec-charger-config = <0>;
	qcom,usb-icl-ua = <3000000>;
	qcom,fcc-max-ua = <6000000>;
	qcom,fv-max-uv = <4450000>;
	qcom,auto-recharge-vbat-mv = <4380000>;
	qcom,chg-term-src = <1>;
	qcom,chg-term-current-ma = <(-220)>;
	qcom,auto-recharge-soc = <99>;
	qcom,step-charging-enable;
	qcom,sw-jeita-enable;
	qcom,charger-temp-max = <800>;
	qcom,smb-temp-max = <800>;
	qcom,wd-bark-time-secs = <16>;
	//qcom,suspend-input-on-debug-batt;
	//qcom,fcc-stepping-enable;
	qcom,lpd-disable;
	dpdm-supply = <&usb2_phy0>;
	qcom,usbpd-phandle = <&pm7250b_pdphy>;
	mi,use-bq-pump;
	qcom,support-conn-therm;
	qcom,reg-dump-enable;
	qcom,disable-suspend-on-collapse;
	mi,support-ffc;
	qcom,distinguish-qc-class-ab;

	qcom,thermal-mitigation = <6000000 5000000 4500000 4000000 3500000 3000000 2900000
		2800000 2600000 2400000 2200000 2000000 1800000 1500000
		1000000>;
	qcom,thermal-mitigation-icl
		= <3000000 3000000 3000000 2400000 2200000 2100000 2000000
		2000000 2000000 1900000 1800000 1600000 1500000 1300000
		1000000>;
	qcom,thermal-mitigation-dcp
		= <1800000 1800000 1800000 1800000 1800000 1800000 1800000
		1800000 1800000 1700000 1600000 1400000 1200000 1100000
		1000000>;
	qcom,thermal-mitigation-qc2
		= <1500000 1500000 1500000 1500000 1450000 1400000 1350000
		1300000 1150000 1100000 1000000 900000 850000 750000
		500000>;
	qcom,thermal-fcc-qc3-normal
		= <6000000 5000000 4500000 4000000 3500000 3000000 2900000
		2800000 2700000 2600000 2400000 2200000 2000000 2000000
		1000000>;
	qcom,thermal-fcc-qc3-cp
		= <6000000 5000000 4500000 4000000 3500000 3300000 3200000
		3100000 3000000 2800000 2600000 2400000 2200000 2000000
		1000000>;
	qcom,thermal-mitigation-pd-base
		= <6000000 5000000 4500000 4000000 3400000 3300000 3200000
		3100000 3000000 2800000 2600000 2400000 2200000 2000000
		1000000>;
	qcom,thermal-fcc-pps-cp
		= <6000000 5400000 4800000 4500000 4000000 3500000 3200000
		3000000 3000000 2600000 2400000 2200000 2200000 2000000
		1000000>;

	vbus-disable-gpio = <&tlmm 67 GPIO_ACTIVE_HIGH>;
	pinctrl-names = "default", "vbus_disable_active", "vbus_disable_suspend";
	pinctrl-0 = <&vbus_disable_suspend>;
	pinctrl-1 = <&vbus_disable_active>;
	pinctrl-2 = <&vbus_disable_suspend>;
};

&pm7250b_pdphy {
	mi,non-qcom-pps-ctrl;
};

&mtp_batterydata {
	qcom,batt-id-range-pct = <15>;
	#include "batterydata-picasso-G7ASIBM4P-4500mah.dtsi"
	#include "batterydata-picasso-G7ANVTBM4P-4500mah.dtsi"
	#include "batterydata-picasso-G7ADEFAULT-4500mah.dtsi"
};

&pm7250b_qg {
	status = "ok";
	io-channels =
		<&pm7250b_vadc ADC_BAT_THERM_PU2>,
		<&pm7250b_vadc ADC_BAT_ID_PU2>;
	io-channel-names =
		"batt-therm",
		"batt-id";
	qcom,battery-data = <&mtp_batterydata>;
	qcom,vbatt-cutoff-mv = <3400>;
	qcom,vbatt-low-mv = <3500>;
	qcom,vbatt-low-cold-mv = <3800>;
	qcom,vbatt-empty-mv = <3100>;
	qcom,vbatt-empty-cold-mv = <3000>;
	qcom,s3-entry-fifo-length = <2>;
	qcom,s3-entry-ibat-ua = <25000>;
	qcom,s3-exit-ibat-ua = <45000>;
	qcom,qg-iterm-ma = <400>;
	qcom,soc_decimal_rate = <
		0  32
		10 30
		20 28
		30 28
		40 28
		50 28
		60 28
		70 28
		80 28
		90 26
		95 10
		99 5>;
	qcom,shutdown-soc-threshold = <10>;
	qcom,tcss-entry-soc = <90>;
	qcom,hold-soc-while-full;
	qcom,linearize-soc;
	qcom,cl-feedback-on;
	qcom,qg-ext-sns;
	qcom,qg-fast-chg-config;
	qcom,tcss-enable;
	qcom,shutdown-delay-enable;
};

&soc {
	cp_qc30 {
		compatible = "xiaomi,cp-qc30";
		status = "ok";
		mi,qc3-bat-volt-max = <4450>;
		mi,qc3-bat-curr-max = <3600>;
		mi,qc3-bus-volt-max = <12000>;
		mi,qc3-bus-curr-max = <2100>;
		//mi,cp-sec-enable;
	};

	usbpd_pm {
		compatible = "xiaomi,usbpd-pm";
		status = "ok";
		mi,pd-bat-volt-max = <4450>;
		mi,pd-bat-curr-max = <6000>;
		mi,pd-bus-volt-max = <12000>;
		mi,pd-bus-curr-max = <3000>;
		mi,pd-bus-curr-compensate = <100>;
		//mi,cp-sec-enable;
	};

	onewire_gpio: onewire_gpio {
		compatible = "xiaomi,onewire_gpio";
		label = "xm_onewire";
		xiaomi,version = <1>;
		xiaomi,ow_gpio = <&tlmm 66 0x00>;
		xiaomi,gpio_number = <66>;
		mi,onewire-gpio-cfg-addr = <0x0f942000 0x4>;
		pinctrl-names = "onewire_active", "onewire_sleep";
		pinctrl-0 = <&onewire_gpio_active>;
		pinctrl-1 = <&onewire_gpio_sleep>;
		status = "ok";
	};
	maxim_ds28e16: maxim_ds28e16 {
		compatible = "maxim,ds28e16";
		label = "max_ds28e16";
		maxim,version = <1>;
		status = "ok";
	};

	fingerprint_goodix {
		compatible = "goodix,fingerprint";
		goodix,gpio-reset = <&tlmm 63 0x0>;
		goodix,gpio-irq = <&tlmm 121 0x0>;
		fp_vdd_vreg-supply = <&pm8150_l13>;
		status = "ok";
	};

	fingerprint_fpc {
               status = "ok";
               compatible = "fpc,fpc1020";
               fpc,gpio_rst    = <&tlmm 63 0x0>;
               fpc,gpio_irq    = <&tlmm 121 0x0>;
               pinctrl-names = "fpc1020_reset_reset",
                       "fpc1020_reset_active",
                       "fpc1020_irq_active";

               pinctrl-0 = <&msm_gpio_63>;
               pinctrl-1 = <&msm_gpio_63_output_high>;
               pinctrl-2 = <&msm_gpio_121>;

       };
       thermal_message: thermal-message {
	       board-sensor = "VIRTUAL-SENSOR";
       };
};

&tlmm {
        /* GPIO_63 : FP_RESET_N */
        msm_gpio_63: msm_gpio_63 {
                mux {
                         pins = "gpio63";
                         function = "gpio";
                };

                config {
                        pins = "gpio63";
                        drive-strength = <2>;
                        bias-disable;
                        output-low;
                };
        };

        /* GPIO_63 : FP_RESET_N, state device active*/
        msm_gpio_63_output_high: msm_gpio_63_output_high {
                mux {
                        pins = "gpio63";
                        function = "gpio";
                };

                config {
                        pins = "gpio63";
                        drive-strength = <2>;
                        bias-disable;
                        output-high;
                };
        };

        /* GPIO_121 : FP_INT_N */
        msm_gpio_121: msm_gpio_121 {
                mux {
                        pins = "gpio121";
                        function = "gpio";
                };

                config {
                        pins = "gpio121";
                        drive-strength = <2>;
                        bias-pull-down;
                };
        };
};

&pm8150_l13 {
	qcom,init-voltage = <2800000>;
};

&usb_qmp_dp_phy {
        vdd-supply = <&vdda_usb_ss_dp_core>;
};

&usb0 {
	qcom,gdsc-collapse-in-host-suspend;
	dwc3@a600000 {
		usb-phy = <&usb2_phy0>, <&usb_nop_phy>;
		maximum-speed = "high-speed";
	};
};

&usb2_phy0 {
	qcom,param-override-seq =
		<0xc8 0x70
		0x24 0x74
		0x64 0x6c>;
};

&sdhc_2 {
	status = "disabled";
};

&pm8008_8 {
	pinctrl-0 = <&pm8008_active>; //liuqinhong@xiaomi.com
};
